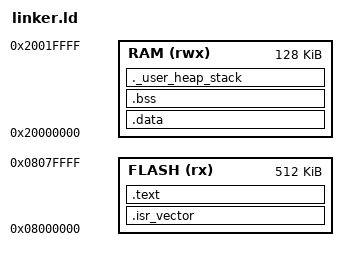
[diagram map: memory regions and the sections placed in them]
ENTRY(Reset_Handler)

/* STM32F411RE memory */
MEMORY
{
  FLASH (rx)  : ORIGIN = 0x08000000, LENGTH = 512K
  RAM   (rwx) : ORIGIN = 0x20000000, LENGTH = 128K
}

/* Stack & Heap size */
_estack = ORIGIN(RAM) + LENGTH(RAM);
_Min_Heap_Size  = 0x400;   /* 1 KB */
_Min_Stack_Size = 0x800;   /* 2 KB */

SECTIONS
{
  .isr_vector :
  {
    KEEP(*(.isr_vector))
  } > FLASH

  .text :
  {
    *(.text*)
    *(.rodata*)
    _etext = .;
  } > FLASH

  .data : AT(_etext)
  {
    _sidata = LOADADDR(.data);
    _sdata = .;
    *(.data*)
    _edata = .;
  } > RAM

  .bss :
  {
    _sbss = .;
    *(.bss*)
    *(COMMON)
    _ebss = .;
  } > RAM

  /* Heap */
  ._user_heap_stack :
  {
    . = ALIGN(8);
    PROVIDE(end = .);
    . += _Min_Heap_Size;
    . += _Min_Stack_Size;
  } > RAM
}

